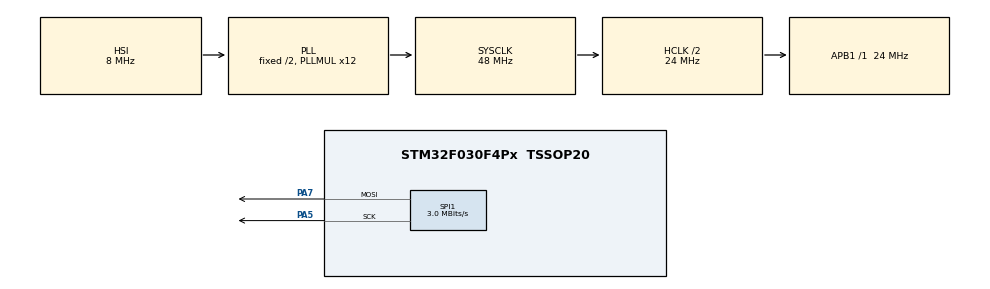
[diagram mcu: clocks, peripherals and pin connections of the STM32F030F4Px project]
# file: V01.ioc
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Dma.Request0=SPI1_TX
Dma.SPI1_TX.0.Direction=DMA_MEMORY_TO_PERIPH
Dma.SPI1_TX.0.Instance=DMA1_Channel3
Dma.SPI1_TX.0.MemDataAlignment=DMA_MDATAALIGN_BYTE
Dma.SPI1_TX.0.MemInc=DMA_MINC_ENABLE
Dma.SPI1_TX.0.Mode=DMA_NORMAL
Dma.SPI1_TX.0.PeriphDataAlignment=DMA_PDATAALIGN_BYTE
Dma.SPI1_TX.0.PeriphInc=DMA_PINC_DISABLE
Dma.SPI1_TX.0.Priority=DMA_PRIORITY_HIGH
Mcu.Family=STM32F0
Mcu.Name=STM32F030F4Px
Mcu.Package=TSSOP20
NVIC.DMA1_Channel2_3_IRQn=true\:0\:0\:false\:false\:true
PA13.Mode=Serial_Wire
PA13.Signal=SYS_SWDIO
PA14.Mode=Serial_Wire
PA14.Signal=SYS_SWCLK
PA5.Mode=TX_Only_Simplex_Unidirect_Master
PA5.Signal=SPI1_SCK
PA7.GPIO_PuPd=GPIO_PULLDOWN
PA7.Mode=TX_Only_Simplex_Unidirect_Master
PA7.Signal=SPI1_MOSI
ProjectManager.HeapSize=0x200
ProjectManager.StackSize=0x400
ProjectManager.TargetToolchain=SW4STM32
RCC.AHBCLKDivider=RCC_SYSCLK_DIV2
RCC.AHBFreq_Value=24000000
RCC.APB1Freq_Value=24000000
RCC.APB1TimFreq_Value=24000000
RCC.HCLKFreq_Value=24000000
RCC.PLLMUL=RCC_PLL_MUL12
RCC.SYSCLKFreq_VALUE=48000000
RCC.SYSCLKSource=RCC_SYSCLKSOURCE_PLLCLK
SPI1.BaudRatePrescaler=SPI_BAUDRATEPRESCALER_8
SPI1.CLKPolarity=SPI_POLARITY_LOW
SPI1.CalculateBaudRate=3.0 MBits/s
SPI1.DataSize=SPI_DATASIZE_5BIT
SPI1.FirstBit=SPI_FIRSTBIT_MSB
SPI1.Mode=SPI_MODE_MASTER
board=V01

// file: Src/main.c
/**
  ******************************************************************************
  * File Name          : main.c
  * Description        : Main program body
  ******************************************************************************
  *
  * COPYRIGHT(c) 2017 STMicroelectronics
  *
  * Redistribution and use in source and binary forms, with or without modification,
  * are permitted provided that the following conditions are met:
  *   1. Redistributions of source code must retain the above copyright notice,
  *      this list of conditions and the following disclaimer.
  *   2. Redistributions in binary form must reproduce the above copyright notice,
  *      this list of conditions and the following disclaimer in the documentation
  *      and/or other materials provided with the distribution.
  *   3. Neither the name of STMicroelectronics nor the names of its contributors
  *      may be used to endorse or promote products derived from this software
  *      without specific prior written permission.
  *
  * THIS SOFTWARE IS PROVIDED BY THE COPYRIGHT HOLDERS AND CONTRIBUTORS "AS IS"
  * AND ANY EXPRESS OR IMPLIED WARRANTIES, INCLUDING, BUT NOT LIMITED TO, THE
  * IMPLIED WARRANTIES OF MERCHANTABILITY AND FITNESS FOR A PARTICULAR PURPOSE ARE
  * DISCLAIMED. IN NO EVENT SHALL THE COPYRIGHT HOLDER OR CONTRIBUTORS BE LIABLE
  * FOR ANY DIRECT, INDIRECT, INCIDENTAL, SPECIAL, EXEMPLARY, OR CONSEQUENTIAL
  * DAMAGES (INCLUDING, BUT NOT LIMITED TO, PROCUREMENT OF SUBSTITUTE GOODS OR
  * SERVICES; LOSS OF USE, DATA, OR PROFITS; OR BUSINESS INTERRUPTION) HOWEVER
  * CAUSED AND ON ANY THEORY OF LIABILITY, WHETHER IN CONTRACT, STRICT LIABILITY,
  * OR TORT (INCLUDING NEGLIGENCE OR OTHERWISE) ARISING IN ANY WAY OUT OF THE USE
  * OF THIS SOFTWARE, EVEN IF ADVISED OF THE POSSIBILITY OF SUCH DAMAGE.
  *
  ******************************************************************************
  */
#include "main.h"
#include "stm32f0xx_hal.h"

/* USER CODE BEGIN Includes */
#include <stdio.h>
#include <stdint.h>
/* USER CODE END Includes */

SPI_HandleTypeDef hspi1;
DMA_HandleTypeDef hdma_spi1_tx;

/* USER CODE BEGIN PV */
/* Private variables ---------------------------------------------------------*/
#define LEDS_COUNT 20
#define BITS_PER_SUBCOLOR 8
#define BITS_PER_COLOR (BITS_PER_SUBCOLOR*3)

uint8_t LEDs_Colors[20][3]={
{64,0,0},
{0,64,0},
{0,0,64},
{64,64,64},
{64,64,0},
{64,0,64},
{0,64,64},
{32,0,0},
{16,0,0},
{8,0,0},
{8,0,0},
{16,0,0},
{32,0,0},
{48,0,0},
{64,0,0},
{64,8,8},
{64,16,16},
{64,32,32},
{64,48,48},
{64,64,64}
};

uint8_t wave_offset=0, R_Wave=0, G_Wave=0, B_Wave=0;
int wave_inc=0, wave_level=0;
uint32_t delay_t;

/* USER CODE END PV */

void SystemClock_Config(void);
void Error_Handler(void);
static void MX_GPIO_Init(void);
static void MX_DMA_Init(void);
static void MX_SPI1_Init(void);

/* USER CODE BEGIN PFP */
/* Private function prototypes -----------------------------------------------*/

/* USER CODE END PFP */

/* USER CODE BEGIN 0 */

// uncomment this line to reverse bit order
//#define BIT_ORDER_REVERSE
// Set only one subcolor
void gen_cmd_setc(uint8_t *buf, char c)
{
    uint8_t  b = 1;
#ifdef BIT_ORDER_REVERSE
    uint8_t *p = buf;
#else
    uint8_t *p = &buf[BITS_PER_SUBCOLOR-1];
#endif
    while (b) {
	*p = c&b ? 14 : 8;	// Why "14" and "8"? I have no idea! Ask AMGladtsin ;)
#ifdef BIT_ORDER_REVERSE        //14 and 8 (0b1110 (---_) and 0b1000 (-___) ) - for generate "Diode bits" - connect loger analyser and read the manual for WS2812B :P (AMGladtsin)
	p++;
#else
	p--;
#endif
	b <<= 1;
    }
    return;
}

// Sets three subcolors to buf
void gen_cmd_setrgb(uint8_t *buf, char r, char g, char b)
{
    gen_cmd_setc( buf,                      r);
    gen_cmd_setc(&buf[  BITS_PER_SUBCOLOR], g);
    gen_cmd_setc(&buf[2*BITS_PER_SUBCOLOR], b);
    return;
}

/* USER CODE END 0 */

int main(void)
{

  /* MCU Configuration----------------------------------------------------------*/

  /* Reset of all peripherals, Initializes the Flash interface and the Systick. */
  HAL_Init();

  /* Configure the system clock */
  SystemClock_Config();

  /* Initialize all configured peripherals */
  MX_GPIO_Init();
  MX_DMA_Init();
  MX_SPI1_Init();

  /* Infinite loop */
  /* USER CODE BEGIN WHILE */
  while (1)
  {

    uint8_t cmd[LEDS_COUNT][BITS_PER_COLOR];
    int i=0;
    while (i<LEDS_COUNT){
	if (i == wave_offset){
		R_Wave = 0;
		G_Wave = 0;
		B_Wave = 0;
	    if (LEDs_Colors[i][1] != 0){
		R_Wave=LEDs_Colors[i][1] + wave_inc;
	    };

	    if (LEDs_Colors[i][0] != 0){
		G_Wave=LEDs_Colors[i][0] + wave_inc;
	    };

	    if (LEDs_Colors[i][2] != 0){
		B_Wave=LEDs_Colors[i][2] + wave_inc;
	    };

	gen_cmd_setrgb(cmd[i], R_Wave, G_Wave, B_Wave);
	} else {
	gen_cmd_setrgb(cmd[i], LEDs_Colors[i][1], LEDs_Colors[i][0], LEDs_Colors[i][2]);
	};
	i++;
}

        HAL_SPI_Transmit_DMA(&hspi1, (uint8_t *)cmd, sizeof(cmd));

if (wave_level > 0 && wave_level < 10 ){
    wave_inc += 8;
    };

if (wave_level >10 && wave_level < 20 ){
    wave_inc -=8;
    };

wave_level++;

if (wave_level > 20){
wave_level = 0;
wave_offset++;
if (wave_offset > LEDS_COUNT){
wave_offset = 0;
};
};

for (delay_t = 0; delay_t < 20000; delay_t++);

//    return 0;

  /* USER CODE END WHILE */

  }

}

/** System Clock Configuration
*/
void SystemClock_Config(void)
{

  RCC_OscInitTypeDef RCC_OscInitStruct;
  RCC_ClkInitTypeDef RCC_ClkInitStruct;

    /**Initializes the CPU, AHB and APB busses clocks
    */
  RCC_OscInitStruct.OscillatorType = RCC_OSCILLATORTYPE_HSI;
  RCC_OscInitStruct.HSIState = RCC_HSI_ON;
  RCC_OscInitStruct.HSICalibrationValue = 16;
  RCC_OscInitStruct.PLL.PLLState = RCC_PLL_ON;
  RCC_OscInitStruct.PLL.PLLSource = RCC_PLLSOURCE_HSI;
  RCC_OscInitStruct.PLL.PLLMUL = RCC_PLL_MUL12;
  RCC_OscInitStruct.PLL.PREDIV = RCC_PREDIV_DIV1;
  if (HAL_RCC_OscConfig(&RCC_OscInitStruct) != HAL_OK)
  {
    Error_Handler();
  }

    /**Initializes the CPU, AHB and APB busses clocks
    */
  RCC_ClkInitStruct.ClockType = RCC_CLOCKTYPE_HCLK|RCC_CLOCKTYPE_SYSCLK
                              |RCC_CLOCKTYPE_PCLK1;
  RCC_ClkInitStruct.SYSCLKSource = RCC_SYSCLKSOURCE_PLLCLK;
  RCC_ClkInitStruct.AHBCLKDivider = RCC_SYSCLK_DIV2;
  RCC_ClkInitStruct.APB1CLKDivider = RCC_HCLK_DIV1;

  if (HAL_RCC_ClockConfig(&RCC_ClkInitStruct, FLASH_LATENCY_0) != HAL_OK)
  {
    Error_Handler();
  }

    /**Configure the Systick interrupt time
    */
  HAL_SYSTICK_Config(HAL_RCC_GetHCLKFreq()/1000);

    /**Configure the Systick
    */
  HAL_SYSTICK_CLKSourceConfig(SYSTICK_CLKSOURCE_HCLK);

  /* SysTick_IRQn interrupt configuration */
  HAL_NVIC_SetPriority(SysTick_IRQn, 0, 0);
}

/* SPI1 init function */
static void MX_SPI1_Init(void)
{

  hspi1.Instance = SPI1;
  hspi1.Init.Mode = SPI_MODE_MASTER;
  hspi1.Init.Direction = SPI_DIRECTION_2LINES;
  hspi1.Init.DataSize = SPI_DATASIZE_5BIT;
  hspi1.Init.CLKPolarity = SPI_POLARITY_LOW;
  hspi1.Init.CLKPhase = SPI_PHASE_1EDGE;
  hspi1.Init.NSS = SPI_NSS_SOFT;
  hspi1.Init.BaudRatePrescaler = SPI_BAUDRATEPRESCALER_8;
  hspi1.Init.FirstBit = SPI_FIRSTBIT_MSB;
  hspi1.Init.TIMode = SPI_TIMODE_DISABLE;
  hspi1.Init.CRCCalculation = SPI_CRCCALCULATION_DISABLE;
  hspi1.Init.CRCPolynomial = 7;
  hspi1.Init.CRCLength = SPI_CRC_LENGTH_DATASIZE;
  hspi1.Init.NSSPMode = SPI_NSS_PULSE_ENABLE;
  if (HAL_SPI_Init(&hspi1) != HAL_OK)
  {
    Error_Handler();
  }

}

static void MX_DMA_Init(void)
{
  /* DMA controller clock enable */
  __HAL_RCC_DMA1_CLK_ENABLE();

  /* DMA interrupt init */
  /* DMA1_Channel2_3_IRQn interrupt configuration */
  HAL_NVIC_SetPriority(DMA1_Channel2_3_IRQn, 0, 0);
  HAL_NVIC_EnableIRQ(DMA1_Channel2_3_IRQn);

}

/** Configure pins as
        * Analog
        * Input
        * Output
        * EVENT_OUT
        * EXTI
*/
static void MX_GPIO_Init(void)
{

  /* GPIO Ports Clock Enable */
  __HAL_RCC_GPIOA_CLK_ENABLE();

}

void Error_Handler(void)
{
  while(1)
  {
  }
}

/************************ (C) COPYRIGHT STMicroelectronics *****END OF FILE****/
